AUTOSAR XML (schema 3.1.2)
package /Components/SWC_ACCmd
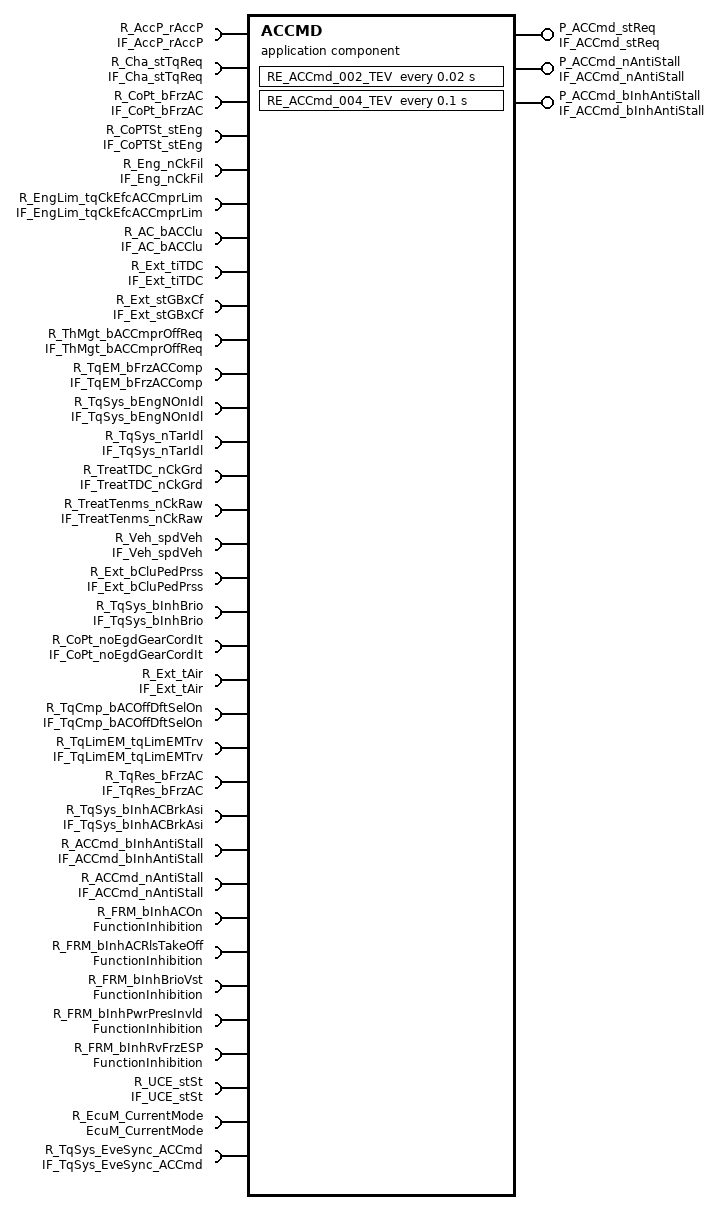
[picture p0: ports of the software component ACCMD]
  application software component type ACCMD
    31 x require port:
      R_AccP_rAccP: unqueued-receiver-com-spec{data-element=AccP_rAccP, init-value=AccP_rAccP_in, resync-time=0}, required-interface=IF_AccP_rAccP
      R_Cha_stTqReq: unqueued-receiver-com-spec{data-element=Cha_stTqReq, init-value=Cha_stTqReq_in, resync-time=0}, required-interface=IF_Cha_stTqReq
      R_CoPt_bFrzAC: unqueued-receiver-com-spec{data-element=CoPt_bFrzAC, init-value=CoPt_bFrzAC_in, resync-time=0}, required-interface=IF_CoPt_bFrzAC
      R_CoPTSt_stEng: unqueued-receiver-com-spec{data-element=CoPTSt_stEng, init-value=ConstantValue, resync-time=0}, required-interface=IF_CoPTSt_stEng
      R_Eng_nCkFil: unqueued-receiver-com-spec{data-element=Eng_nCkFil, init-value=Eng_nCkFil_in, resync-time=0}, required-interface=IF_Eng_nCkFil
      R_EngLim_tqCkEfcACCmprLim: unqueued-receiver-com-spec{data-element=EngLim_tqCkEfcACCmprLim, init-value=EngLim_tqCkEfcACCmprLim_in, resync-time=0}, required-interface=IF_EngLim_tqCkEfcACCmprLim
      R_AC_bACClu: unqueued-receiver-com-spec{data-element=AC_bACClu, init-value=AC_bACClu_in, resync-time=0}, required-interface=IF_AC_bACClu
      R_Ext_tiTDC: unqueued-receiver-com-spec{data-element=Ext_tiTDC, init-value=Ext_tiTDC_in, resync-time=0}, required-interface=IF_Ext_tiTDC
      R_Ext_stGBxCf: unqueued-receiver-com-spec{data-element=Ext_stGBxCf, init-value=Ext_stGBxCf_in, resync-time=0}, required-interface=IF_Ext_stGBxCf
      R_ThMgt_bACCmprOffReq: unqueued-receiver-com-spec{data-element=ThMgt_bACCmprOffReq, init-value=ThMgt_bACCmprOffReq_in, resync-time=0}, required-interface=IF_ThMgt_bACCmprOffReq
      R_TqEM_bFrzACComp: unqueued-receiver-com-spec{data-element=TqEM_bFrzACComp, init-value=TqEM_bFrzACComp_in, resync-time=0}, required-interface=IF_TqEM_bFrzACComp
      R_TqSys_bEngNOnIdl: unqueued-receiver-com-spec{data-element=TqSys_bEngNOnIdl, init-value=TqSys_bEngNOnIdl_in, resync-time=0}, required-interface=IF_TqSys_bEngNOnIdl
      R_TqSys_nTarIdl: unqueued-receiver-com-spec{data-element=TqSys_nTarIdl, init-value=TqSys_nTarIdl_in, resync-time=0}, required-interface=IF_TqSys_nTarIdl
      R_TreatTDC_nCkGrd: unqueued-receiver-com-spec{data-element=TreatTDC_nCkGrd, init-value=TreatTDC_nCkGrd_in, resync-time=0}, required-interface=IF_TreatTDC_nCkGrd
      R_TreatTenms_nCkRaw: unqueued-receiver-com-spec{data-element=TreatTenms_nCkRaw, init-value=TreatTenms_nCkRaw_in, resync-time=0}, required-interface=IF_TreatTenms_nCkRaw
      R_Veh_spdVeh: unqueued-receiver-com-spec{data-element=Veh_spdVeh, init-value=Veh_spdVeh_in, resync-time=0}, required-interface=IF_Veh_spdVeh
      R_Ext_bCluPedPrss: unqueued-receiver-com-spec{data-element=Ext_bCluPedPrss, init-value=Ext_bCluPedPrss_in, resync-time=0}, required-interface=IF_Ext_bCluPedPrss
      R_TqSys_bInhBrio: unqueued-receiver-com-spec{data-element=TqSys_bInhBrio, init-value=TqSys_bInhBrio_in, resync-time=0}, required-interface=IF_TqSys_bInhBrio
      R_CoPt_noEgdGearCordIt: unqueued-receiver-com-spec{data-element=CoPt_noEgdGearCordIt, init-value=CoPt_noEgdGearCordIt_in, resync-time=0}, required-interface=IF_CoPt_noEgdGearCordIt
      R_Ext_tAir: unqueued-receiver-com-spec{data-element=Ext_tAir, init-value=Ext_tAir_in, resync-time=0}, required-interface=IF_Ext_tAir
      R_TqCmp_bACOffDftSelOn: unqueued-receiver-com-spec{data-element=TqCmp_bACOffDftSelOn, init-value=TqCmp_bACOffDftSelOn_in, resync-time=0}, required-interface=IF_TqCmp_bACOffDftSelOn
      R_TqLimEM_tqLimEMTrv: unqueued-receiver-com-spec{data-element=TqLimEM_tqLimEMTrv, init-value=TqLimEM_tqLimEMTrv_in, resync-time=0}, required-interface=IF_TqLimEM_tqLimEMTrv
      R_TqRes_bFrzAC: unqueued-receiver-com-spec{data-element=TqRes_bFrzAC, init-value=TqRes_bFrzAC_in, resync-time=0}, required-interface=IF_TqRes_bFrzAC
      R_TqSys_bInhACBrkAsi: unqueued-receiver-com-spec{data-element=TqSys_bInhACBrkAsi, init-value=TqSys_bInhACBrkAsi_in, resync-time=0}, required-interface=IF_TqSys_bInhACBrkAsi
      R_ACCmd_bInhAntiStall: unqueued-receiver-com-spec{data-element=ACCmd_bInhAntiStall, init-value=ACCmd_bInhAntiStall_in, resync-time=0}, required-interface=IF_ACCmd_bInhAntiStall
      R_ACCmd_nAntiStall: unqueued-receiver-com-spec{data-element=ACCmd_nAntiStall, init-value=ACCmd_nAntiStall_in, resync-time=0}, required-interface=IF_ACCmd_nAntiStall
      R_FRM_bInhACOn: required-interface=FunctionInhibition
      R_FRM_bInhACRlsTakeOff: required-interface=FunctionInhibition
      R_FRM_bInhBrioVst: required-interface=FunctionInhibition
      R_FRM_bInhPwrPresInvld: required-interface=FunctionInhibition
      R_FRM_bInhRvFrzESP: required-interface=FunctionInhibition
    provide port P_ACCmd_stReq: unqueued-sender-com-spec{data-element=ACCmd_stReq, can-invalidate=false, init-value=ACCmd_stReq_out}, provided-interface=IF_ACCmd_stReq
    provide port P_ACCmd_nAntiStall: unqueued-sender-com-spec{data-element=ACCmd_nAntiStall, can-invalidate=false, init-value=ACCmd_nAntiStall_out}, provided-interface=IF_ACCmd_nAntiStall
    provide port P_ACCmd_bInhAntiStall: unqueued-sender-com-spec{data-element=ACCmd_bInhAntiStall, can-invalidate=false, init-value=ACCmd_bInhAntiStall_out}, provided-interface=IF_ACCmd_bInhAntiStall
    require port R_UCE_stSt: required-interface=IF_UCE_stSt
    require port R_EcuM_CurrentMode: required-interface=EcuM_CurrentMode
    require port R_TqSys_EveSync_ACCmd: unqueued-receiver-com-spec{data-element=TqSys_EveSync_ACCmd, init-value=ConstantValue1, resync-time=0}, required-interface=IF_TqSys_EveSync_ACCmd
  35 x constant specification:
    AC_bACClu_in
      value:
        boolean literal AC_bACClu_in: type=DT_AC_bACClu, value=false
    ACCmd_bInhACOn_irv
      value:
        boolean literal ACCmd_bInhACOn_irv: type=DT_ACCmd_bInhACOn_irv, value=false
    ACCmd_bInhACOn_irv_Cst
      value:
        boolean literal ACCmd_bInhACOn_irv_Cst: type=DT_ACCmd_bInhTakeOff_irv, value=false
    ACCmd_bInhAntiStall_in
      value:
        boolean literal ACCmd_bInhAntiStall_in: type=DT_ACCmd_bInhAntiStall, value=false
    ACCmd_bInhAntiStall_out
      value:
        boolean literal ACCmd_bInhAntiStall_out: type=DT_ACCmd_bInhAntiStall, value=false
    ACCmd_bInhAst_irv_Cst
      value:
        boolean literal ACCmd_bInhAst_irv_Cst: type=DT_ACCmd_bInhAst_irv, value=false
    ACCmd_bInhTDCClc_irv
      value:
        boolean literal ACCmd_bInhTDCClc_irv: type=DT_ACCmd_bInhTDCClc_irv, value=false
    ACCmd_nAntiStall_in
      value:
        integer literal ACCmd_nAntiStall_in: type=DT_ACCmd_nAntiStall, value=0
    ACCmd_nAntiStall_out
      value:
        integer literal ACCmd_nAntiStall_out: type=DT_ACCmd_nAntiStall, value=0
    ACCmd_spdVeh_irv
      value:
        integer literal ACCmd_spdVeh_irv: type=DT_ACCmd_spdVeh_irv, value=0
    ACCmd_stReq_out
      value:
        integer literal ACCmd_stReq_out: type=DT_ACCmd_stReq, value=1
    AccP_rAccP_in
      value:
        integer literal AccP_rAccP_in: type=DT_AccP_rAccP, value=0
    Cha_stTqReq_in
      value:
        integer literal Cha_stTqReq_in: type=DT_Cha_stTqReq, value=0
    ConstantValue
      value:
        integer literal ConstantValue: type=DT_CoPTSt_stEng, value=1
    ConstantValue1
      value:
        boolean literal ConstantValue1: type=DT_TqSys_EveSync_ACCmd, value=false
    CoPt_bFrzAC_in
      value:
        boolean literal CoPt_bFrzAC_in: type=DT_CoPt_bFrzAC, value=false
    CoPt_noEgdGearCordIt_in
      value:
        integer literal CoPt_noEgdGearCordIt_in: type=DT_CoPt_noEgdGearCordIt, value=0
    Eng_nCkFil_in
      value:
        integer literal Eng_nCkFil_in: type=DT_Eng_nCkFil, value=0
    EngLim_tqCkEfcACCmprLim_in
      value:
        integer literal EngLim_tqCkEfcACCmprLim_in: type=DT_EngLim_tqCkEfcACCmprLim, value=32000
    Ext_bCluPedPrss_in
      value:
        boolean literal Ext_bCluPedPrss_in: type=DT_Ext_bCluPedPrss, value=false
    Ext_stGBxCf_in
      value:
        integer literal Ext_stGBxCf_in: type=DT_Ext_stGBxCf, value=0
    Ext_tAir_in
      value:
        integer literal Ext_tAir_in: type=DT_Ext_tAir, value=20
    Ext_tiTDC_in
      value:
        integer literal Ext_tiTDC_in: type=DT_Ext_tiTDC, value=100
    ThMgt_bACCmprOffReq_in
      value:
        boolean literal ThMgt_bACCmprOffReq_in: type=DT_ThMgt_bACCmprOffReq, value=false
    TqCmp_bACOffDftSelOn_in
      value:
        boolean literal TqCmp_bACOffDftSelOn_in: type=DT_TqCmp_bACOffDftSelOn, value=false
    TqEM_bFrzACComp_in
      value:
        boolean literal TqEM_bFrzACComp_in: type=DT_TqEM_bFrzACComp, value=false
    TqLimEM_tqLimEMTrv_in
      value:
        integer literal TqLimEM_tqLimEMTrv_in: type=DT_TqLimEM_tqLimEMTrv, value=0
    TqRes_bFrzAC_in
      value:
        boolean literal TqRes_bFrzAC_in: type=DT_TqRes_bFrzAC, value=false
    TqSys_bEngNOnIdl_in
      value:
        boolean literal TqSys_bEngNOnIdl_in: type=DT_TqSys_bEngNOnIdl, value=true
    TqSys_bInhACBrkAsi_in
      value:
        boolean literal TqSys_bInhACBrkAsi_in: type=DT_TqSys_bInhACBrkAsi, value=false
    TqSys_bInhBrio_in
      value:
        boolean literal TqSys_bInhBrio_in: type=DT_TqSys_bInhBrio, value=false
    TqSys_nTarIdl_in
      value:
        integer literal TqSys_nTarIdl_in: type=DT_TqSys_nTarIdl, value=0
    TreatTDC_nCkGrd_in
      value:
        integer literal TreatTDC_nCkGrd_in: type=DT_TreatTDC_nCkGrd, value=0
    TreatTenms_nCkRaw_in
      value:
        integer literal TreatTenms_nCkRaw_in: type=DT_TreatTenms_nCkRaw, value=0
    Veh_spdVeh_in
      value:
        integer literal Veh_spdVeh_in: type=DT_Veh_spdVeh, value=0
  internal behavior IB_ACCmd: component=ACCMD
    timing event EV_TqSys_Sdl20ms_ACCmd: start-on-event=RE_ACCmd_002_TEV, period=0.02
    data received event EV_TqSys_EveSync_ACCmd: start-on-event=RE_ACCmd_003_DRE, data=R_TqSys_EveSync_ACCmd.TqSys_EveSync_ACCmd
    timing event EV_TqSys_Sdl100ms_ACCmd: start-on-event=RE_ACCmd_004_TEV, period=0.1
    mode switch event EV_ACCmd_001_MSE: start-on-event=RE_ACCmd_001_MSE, activation=ENTRY, mode=R_EcuM_CurrentMode.currentMode.RUN
    5 x inter runnable variable, all with sw-calibration-access=READ-WRITE, communication-approach=EXPLICIT:
      ACCmd_bInhTDCClc_irv: type=DT_ACCmd_bInhTDCClc_irv, init-value=ACCmd_bInhTDCClc_irv
      ACCmd_bInhACOn_irv: type=DT_ACCmd_bInhACOn_irv, init-value=ACCmd_bInhACOn_irv
      ACCmd_bInhTakeOff_irv: type=DT_ACCmd_bInhTakeOff_irv, init-value=ACCmd_bInhACOn_irv_Cst
      ACCmd_bInhAst_irv: type=DT_ACCmd_bInhAst_irv, init-value=ACCmd_bInhAst_irv_Cst
      ACCmd_spdVeh_irv: type=DT_ACCmd_spdVeh_irv, init-value=ACCmd_spdVeh_irv
    4 x runnable:
      RE_ACCmd_003_DRE: read-variable=[ACCmd_spdVeh_irv, ACCmd_bInhTDCClc_irv], written-variable=ACCmd_bInhTakeOff_irv
        9 x data receive point:
          dr_TreatTenms_nCkRaw: data-element=R_TreatTenms_nCkRaw.TreatTenms_nCkRaw
          dr_TqSys_nTarIdl: data-element=R_TqSys_nTarIdl.TqSys_nTarIdl
          dr_AccP_rAccP: data-element=R_AccP_rAccP.AccP_rAccP
          dr_AC_bACClu: data-element=R_AC_bACClu.AC_bACClu
          dr_TqSys_bEngNOnIdl: data-element=R_TqSys_bEngNOnIdl.TqSys_bEngNOnIdl
          dr_CoPt_noEgdGearCordIt: data-element=R_CoPt_noEgdGearCordIt.CoPt_noEgdGearCordIt
          dr_Ext_tiTDC: data-element=R_Ext_tiTDC.Ext_tiTDC
          dr_TqSys_EveSync_ACCmd: data-element=R_TqSys_EveSync_ACCmd.TqSys_EveSync_ACCmd
          dr_TreatTDC_nCkGrd: data-element=R_TreatTDC_nCkGrd.TreatTDC_nCkGrd
        data send point ds_ACCmd_nAntiStall: data-element=P_ACCmd_nAntiStall.ACCmd_nAntiStall
        data send point ds_ACCmd_bInhAntiStall: data-element=P_ACCmd_bInhAntiStall.ACCmd_bInhAntiStall
      RE_ACCmd_001_MSE: written-variable=[ACCmd_spdVeh_irv, ACCmd_bInhACOn_irv, ACCmd_bInhTakeOff_irv, ACCmd_bInhTDCClc_irv, ACCmd_bInhAst_irv]
        data send point ds_ACCmd_stReq: data-element=P_ACCmd_stReq.ACCmd_stReq
        data send point ds_ACCmd_bInhAntiStall: data-element=P_ACCmd_bInhAntiStall.ACCmd_bInhAntiStall
        data send point ds_ACCmd_nAntiStall: data-element=P_ACCmd_nAntiStall.ACCmd_nAntiStall
      RE_ACCmd_004_TEV: written-variable=[ACCmd_bInhAst_irv, ACCmd_bInhACOn_irv]
        data receive point dr_TqCmp_bACOffDftSelOn: data-element=R_TqCmp_bACOffDftSelOn.TqCmp_bACOffDftSelOn
        data receive point dr_Ext_tAir: data-element=R_Ext_tAir.Ext_tAir
        data receive point dr_CoPTSt_stEng: data-element=R_CoPTSt_stEng.CoPTSt_stEng
        sync call scp_GetFunctionPermission4: operation=R_FRM_bInhPwrPresInvld.GetFunctionPermission
        sync call scp_GetFunctionPermission3: operation=R_FRM_bInhACOn.GetFunctionPermission
      RE_ACCmd_002_TEV: read-variable=[ACCmd_bInhACOn_irv, ACCmd_bInhAst_irv, ACCmd_bInhTakeOff_irv], written-variable=[ACCmd_bInhTDCClc_irv, ACCmd_spdVeh_irv]
        21 x data receive point:
          dr_TqSys_bInhACBrkAsi: data-element=R_TqSys_bInhACBrkAsi.TqSys_bInhACBrkAsi
          dr_Eng_nCkFil: data-element=R_Eng_nCkFil.Eng_nCkFil
          dr_CoPt_bFrzAC: data-element=R_CoPt_bFrzAC.CoPt_bFrzAC
          dr_EngLim_tqCkEfcACCmprLim: data-element=R_EngLim_tqCkEfcACCmprLim.EngLim_tqCkEfcACCmprLim
          dr_Ext_stGBxCf: data-element=R_Ext_stGBxCf.Ext_stGBxCf
          dr_Ext_tAir: data-element=R_Ext_tAir.Ext_tAir
          dr_Veh_spdVeh: data-element=R_Veh_spdVeh.Veh_spdVeh
          dr_TqSys_bInhBrio: data-element=R_TqSys_bInhBrio.TqSys_bInhBrio
          dr_CoPTSt_stEng: data-element=R_CoPTSt_stEng.CoPTSt_stEng
          dr_ACCmd_bInhAntiStall: data-element=R_ACCmd_bInhAntiStall.ACCmd_bInhAntiStall
          dr_TqSys_bEngNOnIdl: data-element=R_TqSys_bEngNOnIdl.TqSys_bEngNOnIdl
          dr_TqLimEM_tqLimEMTrv: data-element=R_TqLimEM_tqLimEMTrv.TqLimEM_tqLimEMTrv
          dr_ACCmd_nAntiStall: data-element=R_ACCmd_nAntiStall.ACCmd_nAntiStall
          dr_TqEM_bFrzACComp: data-element=R_TqEM_bFrzACComp.TqEM_bFrzACComp
          dr_CoPt_noEgdGearCordIt: data-element=R_CoPt_noEgdGearCordIt.CoPt_noEgdGearCordIt
          dr_ThMgt_bACCmprOffReq: data-element=R_ThMgt_bACCmprOffReq.ThMgt_bACCmprOffReq
          dr_Ext_bCluPedPrss: data-element=R_Ext_bCluPedPrss.Ext_bCluPedPrss
          dr_Cha_stTqReq: data-element=R_Cha_stTqReq.Cha_stTqReq
          dr_TreatTenms_nCkRaw: data-element=R_TreatTenms_nCkRaw.TreatTenms_nCkRaw
          dr_AccP_rAccP: data-element=R_AccP_rAccP.AccP_rAccP
          dr_TqRes_bFrzAC: data-element=R_TqRes_bFrzAC.TqRes_bFrzAC
        data send point ds_ACCmd_stReq: data-element=P_ACCmd_stReq.ACCmd_stReq
        sync call scp_GetFunctionPermission21: operation=R_FRM_bInhRvFrzESP.GetFunctionPermission
        sync call scp_GetFunctionPermission20: operation=R_FRM_bInhBrioVst.GetFunctionPermission
        sync call scp_GetFunctionPermission19: operation=R_FRM_bInhACRlsTakeOff.GetFunctionPermission
  swc implementation Imp_ACCmd: programming-language=C, behavior=IB_ACCmd
    code-descriptors:
      code CodeDescriptor: type=SRC
        11 x xfile:
          ACCmd_c: url=ACCmd.c
          RE_ACCmd_002_TEV_h: url=RE_ACCmd_002_TEV.h
          RE_ACCmd_002_TEV_c: url=RE_ACCmd_002_TEV.c
          RE_ACCmd_004_TEV_h: url=RE_ACCmd_004_TEV.h
          ACCmd_calibrations_c: url=ACCmd_calibrations.c
          RE_ACCmd_003_DRE_h: url=RE_ACCmd_003_DRE.h
          ACCmd_calibrations_h: url=ACCmd_calibrations.h
          ACCmd_MemMap_h: url=ACCmd_MemMap.h
          RE_ACCmd_004_TEV_c: url=RE_ACCmd_004_TEV.c
          ACCmd_h: url=ACCmd.h
          RE_ACCmd_003_DRE_c: url=RE_ACCmd_003_DRE.c
package /Components/SWC_ACCmd/ACCmd_IRVDatatypes
  4 x boolean type, all with base-type=boolean:
    DT_ACCmd_bInhACOn_irv
    DT_ACCmd_bInhAst_irv
    DT_ACCmd_bInhTakeOff_irv
    DT_ACCmd_bInhTDCClc_irv
  integer type DT_ACCmd_spdVeh_irv: base-type=uint16, lower-limit=0, upper-limit=65535
